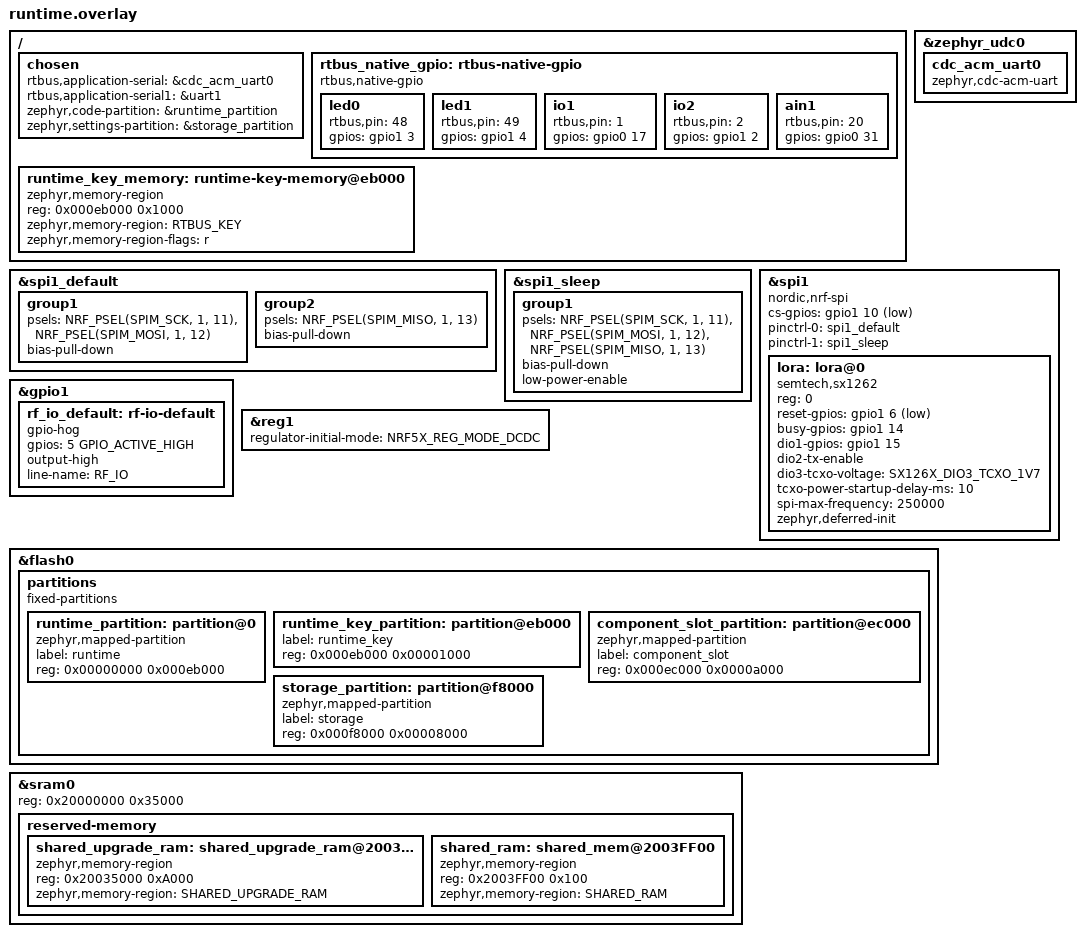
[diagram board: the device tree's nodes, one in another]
/* SPDX-License-Identifier: MPL-2.0 */
/ {
    chosen {
        /delete-property/ zephyr,console;
        /delete-property/ zephyr,uart-mcumgr;
        /delete-property/ zephyr,shell-uart;
        rtbus,application-serial = &cdc_acm_uart0;
        rtbus,application-serial1 = &uart1;
        zephyr,code-partition = &runtime_partition;
        zephyr,settings-partition = &storage_partition;
    };

    rtbus_native_gpio: rtbus-native-gpio {
        compatible = "rtbus,native-gpio";

        /*
         * Application GPIO export map.
         *
         * Only board-owned pins that are safe for native applications should
         * be listed here.
         */

        led0 {
            rtbus,pin = <48>;
            gpios = <&gpio1 3 GPIO_ACTIVE_HIGH>;
        };

        led1 {
            rtbus,pin = <49>;
            gpios = <&gpio1 4 GPIO_ACTIVE_HIGH>;
        };

		io1 {
			rtbus,pin = <1>;
			gpios = <&gpio0 17 GPIO_ACTIVE_HIGH>;
		};

		io2 {
			rtbus,pin = <2>;
			gpios = <&gpio1 2 GPIO_ACTIVE_HIGH>;
		};

		ain1 {
			rtbus,pin = <20>;
			gpios = <&gpio0 31 GPIO_ACTIVE_HIGH>;
		};
    };
};

&zephyr_udc0 {
    status = "okay";
    
    cdc_acm_uart0: cdc_acm_uart0 {
        compatible = "zephyr,cdc-acm-uart";
    };
};

&spi1_default {
	group1 {
		psels = <NRF_PSEL(SPIM_SCK, 1, 11)>,
			<NRF_PSEL(SPIM_MOSI, 1, 12)>;
		bias-pull-down;
	};

	group2 {
		psels = <NRF_PSEL(SPIM_MISO, 1, 13)>;
		bias-pull-down;
	};
};

&spi1_sleep {
	group1 {
		psels = <NRF_PSEL(SPIM_SCK, 1, 11)>,
			<NRF_PSEL(SPIM_MOSI, 1, 12)>,
			<NRF_PSEL(SPIM_MISO, 1, 13)>;
		bias-pull-down;
		low-power-enable;
	};
};

&spi1 {
	compatible = "nordic,nrf-spi";
	status = "okay";
	cs-gpios = <&gpio1 10 (GPIO_ACTIVE_LOW)>;

	pinctrl-0 = <&spi1_default>;
	pinctrl-1 = <&spi1_sleep>;
	pinctrl-names = "default", "sleep";

	lora: lora@0 {
		compatible = "semtech,sx1262";
		reg = <0>;
		/delete-property/ rx-enable-gpios;
		reset-gpios = <&gpio1 6 (GPIO_ACTIVE_LOW | GPIO_PULL_UP)>;
		busy-gpios = <&gpio1 14 (GPIO_ACTIVE_HIGH | GPIO_PULL_DOWN)>;
		dio1-gpios = <&gpio1 15 (GPIO_ACTIVE_HIGH | GPIO_PULL_DOWN)>;
		dio2-tx-enable;
		dio3-tcxo-voltage = <SX126X_DIO3_TCXO_1V7>;
		tcxo-power-startup-delay-ms = <10>;
		spi-max-frequency = <250000>;
	};
};


&lora {
	zephyr,deferred-init;
};

&gpio1 {
	/* P1.05: board RF IO, not RX/TX switch; hold high at boot */
	rf_io_default: rf-io-default {
		gpio-hog;
		gpios = <5 GPIO_ACTIVE_HIGH>;
		output-high;
		line-name = "RF_IO";
	};
};

&reg1 {
	regulator-initial-mode = <NRF5X_REG_MODE_DCDC>;
};

&flash0 {
	/delete-node/ partitions;
	partitions {
		compatible = "fixed-partitions";
		#address-cells = <1>;
		#size-cells = <1>;

		runtime_partition: partition@0 {
			compatible = "zephyr,mapped-partition";
			label = "runtime";
			reg = <0x00000000 0x000eb000>;
		};

		runtime_key_partition: partition@eb000 {
			label = "runtime_key";
			reg = <0x000eb000 0x00001000>;
		};

		component_slot_partition: partition@ec000 {
			compatible = "zephyr,mapped-partition";
			label = "component_slot";
			reg = <0x000ec000 0x0000a000>;
		};

		storage_partition: partition@f8000 {
			compatible = "zephyr,mapped-partition";
			label = "storage";
			reg = <0x000f8000 0x00008000>;
		};
	};
};

&sram0 {
    /*
     * Reserve the top of SRAM for runtime-owned memory windows.
     *
     * shared_upgrade_ram is a 40 KiB pool used by firmware patch staging.
     * The optional native module demo borrows the front of the same pool for
     * module globals until a patch upgrade takes ownership.
     */
    reg = <0x20000000 0x35000>;

    reserved-memory {
        #address-cells = <1>;
        #size-cells = <1>;
        ranges;

        shared_upgrade_ram: shared_upgrade_ram@20035000 {
            compatible = "zephyr,memory-region";
            reg = <0x20035000 0xA000>;
            zephyr,memory-region = "SHARED_UPGRADE_RAM";
        };

        /* Place the shared region at the fixed address 0x2003FF00. */
        shared_ram: shared_mem@2003FF00 {
            compatible = "zephyr,memory-region";
            reg = <0x2003FF00 0x100>;
            zephyr,memory-region = "SHARED_RAM";
        };
    };
};

/* Link the default public key into the same independent Flash partition. */
/ {
	runtime_key_memory: runtime-key-memory@eb000 {
		compatible = "zephyr,memory-region";
		reg = <0x000eb000 0x1000>;
		zephyr,memory-region = "RTBUS_KEY";
		zephyr,memory-region-flags = "r";
	};
};
